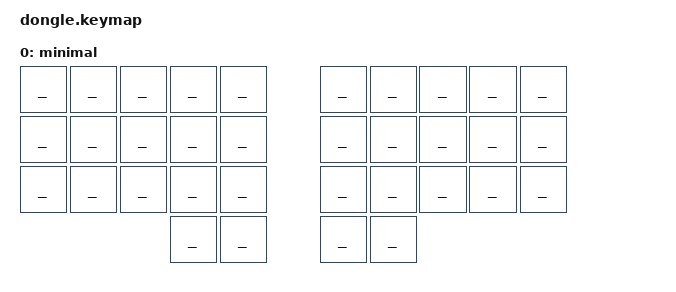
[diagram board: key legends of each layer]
#include "../../../shared.dtsi"

// Dongle doesn’t have actual keys, just behaviors for wireless, combos, leader key
ZMK_LAYER(minimal,
    ___ ___ ___ ___ ___ , ___ ___ ___ ___ ___,
    ___ ___ ___ ___ ___ , ___ ___ ___ ___ ___,
    ___ ___ ___ ___ ___ , ___ ___ ___ ___ ___,
              ___ ___ , ___ ___
);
